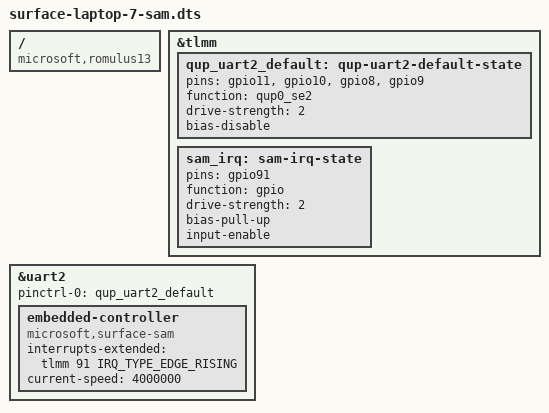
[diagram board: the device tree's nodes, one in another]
// SPDX-License-Identifier: GPL-2.0-only
/*
 * Surface Laptop 7 (Romulus) Surface Aggregator Module overlay.
 * Connects the SAM EC to UART2 with hardware flow control.
 */

/dts-v1/;
/plugin/;

#define IRQ_TYPE_EDGE_RISING 1

/ {
	compatible = "microsoft,romulus13", "microsoft,romulus15", "qcom,x1e80100";
};

&tlmm {
	qup_uart2_default: qup-uart2-default-state {
		pins = "gpio11", "gpio10", "gpio8", "gpio9";
		function = "qup0_se2";
		drive-strength = <2>;
		bias-disable;
	};

	sam_irq: sam-irq-state {
		pins = "gpio91";
		function = "gpio";
		drive-strength = <2>;
		bias-pull-up;
		input-enable;
	};
};

&uart2 {
	status = "okay";

	pinctrl-0 = <&qup_uart2_default>;
	pinctrl-names = "default";

	embedded-controller {
		compatible = "microsoft,surface-sam";
		interrupts-extended = <&tlmm 91 IRQ_TYPE_EDGE_RISING>;
		current-speed = <4000000>;
	};
};
